# STLUX285A register map
Vendor: STMicroelectronics; Series: STLUX; File version: 1.0
Digital controllers for lighting and power conversion applications with up to 6 programmable PWM generators, 96 MHz PLL, DALI
CPU: other r1p0, big endian, no MPU, no FPU, 4 interrupt priority bits
Registers are 8-bit, read-write, reset 0x0 unless marked. A register's access mark holds for its fields unless they carry their own. Offsets are from the block's base; lines under a group give offsets from that group; [hi:lo] are bit positions; {n}, {i} and the like mark numbered series; 'fields as' and 'values as' point back to an identical list; <NAME> marks a mode.

## Memory map
0x00004800 OPT blocks up to offset 0x80
0x00005000 PORT0 size 0x5
0x00005005 PORT1 size 0x5
0x00005010 MSC blocks up to offset 0x2E
0x0000505A FLASH blocks up to offset 0xE
0x000050B3 RST size 0x1
0x000050B4 CLK blocks up to offset 0x1C
0x000050D1 WDG blocks up to offset 0x12
0x000050F0 AWU size 0x3
0x00005210 I2C blocks up to offset 0xE
0x00005230 UART blocks up to offset 0xB
0x00005340 STMR size 0x9
0x000053C0 DALI size 0xA
0x00005400 ADC size 0x16
0x00005500 SMED0 size 0x24
0x00005540 SMED1 size 0x24
0x00005580 SMED2 size 0x24
0x000055C0 SMED3 size 0x24
0x00005600 SMED4 size 0x24
0x00005640 SMED5 size 0x24
0x00007F60 SYS blocks up to offset 0x21
0x00007F70 ITC size 0x8

## Interrupts
1 Interrupt_IRQ1 (AWU) — Interrupt_IRQ1 interrupt
2 Interrupt_IRQ2 (CLK, ITC) — Interrupt_IRQ2 interrupt
6 Interrupt_IRQ6 (SMED0) — Interrupt_IRQ6 interrupt
7 Interrupt_IRQ7 (SMED1) — Interrupt_IRQ7 interrupt
15 Interrupt_IRQ15 (SMED2) — Interrupt_IRQ15 interrupt
16 Interrupt_IRQ16 (SMED3) — Interrupt_IRQ16 interrupt
17 Interrupt_IRQ17 (UART) — Interrupt_IRQ17 interrupt
18 Interrupt_IRQ18 (UART) — Interrupt_IRQ18 interrupt
19 Interrupt_IRQ19 (I2C) — Interrupt_IRQ19 interrupt
22 Interrupt_IRQ22 (ADC) — Interrupt_IRQ22 interrupt
23 Interrupt_IRQ23 (STMR) — Interrupt_IRQ23 interrupt
24 Interrupt_IRQ24 (FLASH) — Interrupt_IRQ24 interrupt
25 Interrupt_IRQ25 (DALI, WDG) — Interrupt_IRQ25 interrupt
26 Interrupt_IRQ26 (SMED4) — Interrupt_IRQ26 interrupt
27 Interrupt_IRQ27 (SMED5) — Interrupt_IRQ27 interrupt

## ADC
Base 0x00005400
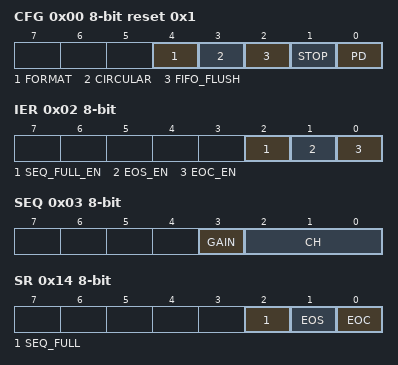
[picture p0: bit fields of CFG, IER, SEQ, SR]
0x00 CFG reset 0x1 — Configuration register
  [4] FORMAT, [3] CIRCULAR, [2] FIFO_FLUSH, [1] STOP, [0] PD
0x01 SOC — Start Of Conversion
  [0] SOC
0x02 IER — Interrupt Enable Register
  [2] SEQ_FULL_EN, [1] EOS_EN, [0] EOC_EN
0x03 SEQ — Sequencer Register
  [3] GAIN, [2:0] CH
{0x4+2i} DATL{i} (i=0..7) — Data Low Register
  [7:0] DATA_LOW
{0x5+2i} DATH{i} (i=0..7) — Data High Register
  [1:0] DATA_HIGH
0x14 SR — Status Register
  [2] SEQ_FULL, [1] EOS, [0] EOC
0x15 DLYCNT — SOC Delay Counter Register
  [7:0] SOC_DLY_CNT

## AWU
Base 0x000050F0
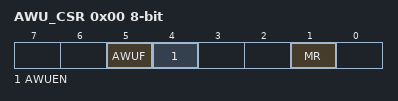
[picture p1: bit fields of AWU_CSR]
0x00 AWU_CSR — AWU control/status register 1
  [5] AWUF, [4] AWUEN, [1] MR
0x01 AWU_APR reset 0x3F — AWU asynchronous prescaler buffer register
  [5:0] APR
0x02 AWU_TBR — AWU timebase selection register
  [3:0] AWUTB

## CLK
Base 0x000050B4
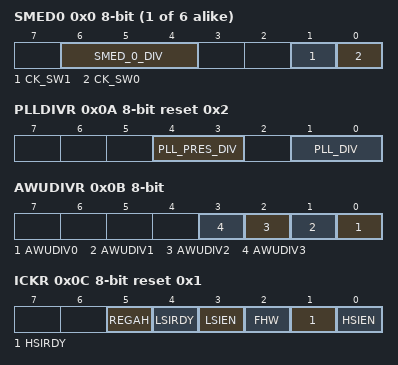
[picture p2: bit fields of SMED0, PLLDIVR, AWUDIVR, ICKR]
{0x0+i} SMED{i} (i=0..5) — SMED{i} clock configuration register
  [6:4] SMED_{i}_DIV, [1] CK_SW1, [0] CK_SW0
0x0A PLLDIVR reset 0x2 — PLL prescaler configuration register
  [4:3] PLL_PRES_DIV, [1:0] PLL_DIV
0x0B AWUDIVR — AWU clock prescaler configuration register
  [n] AWUDIV{n} (n=0..3)
0x0C ICKR reset 0x1 — Internal clock control register
  [5] REGAH, [4] LSIRDY, [3] LSIEN, [2] FHW, [1] HSIRDY, [0] HSIEN
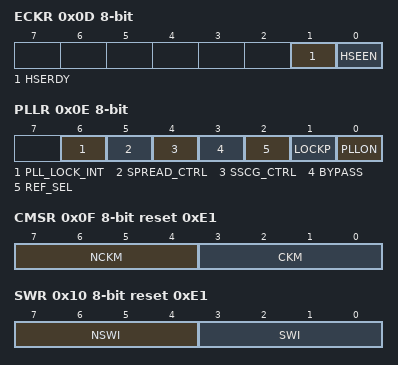
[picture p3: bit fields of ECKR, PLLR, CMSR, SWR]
0x0D ECKR — External clock control register
  [1] HSERDY, [0] HSEEN
0x0E PLLR — External clock control register
  [6] PLL_LOCK_INT, [5] SPREAD_CTRL, [4] SSCG_CTRL, [3] BYPASS, [2] REF_SEL, [1] LOCKP, [0] PLLON
0x0F CMSR reset 0xE1 — Clock master status register
  [7:4] NCKM, [3:0] CKM
0x10 SWR reset 0xE1 — Clock master switch register
  [7:4] NSWI, [3:0] SWI
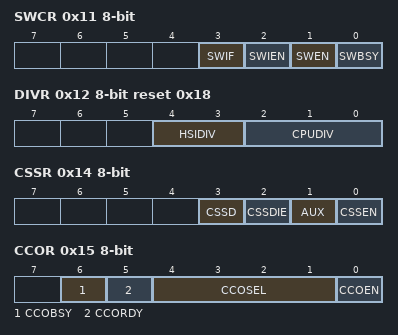
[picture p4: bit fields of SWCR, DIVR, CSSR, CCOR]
0x11 SWCR — Clock switch control register
  [3] SWIF, [2] SWIEN, [1] SWEN, [0] SWBSY
0x12 DIVR reset 0x18 — Clock divider register
  [4:3] HSIDIV, [2:0] CPUDIV
0x13 PCKENR1 reset 0xFF — Peripheral clock gating register 1
  [7:0] PCKEN
0x14 CSSR — Clock security system register
  [3] CSSD, [2] CSSDIE, [1] AUX, [0] CSSEN
0x15 CCOR — Configurable clock control register
  [6] CCOBSY, [5] CCORDY, [4:1] CCOSEL, [0] CCOEN
0x16 PCKENR2 reset 0xFF — Peripheral clock gating register 2
  [7:0] PCKEN
0x18 HSITRIMR — HSI clock calibration trimming register
  [3:0] HSITRIM
0x19 SWIMCCR — SWIM clock control register
  [0] SWIMCLK
0x1A CCODIVR — CCO divider register
  [7:0] CCODIV
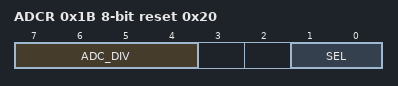
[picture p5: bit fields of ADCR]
0x1B ADCR reset 0x20 — ADC clock configuration register
  [7:4] ADC_DIV, [1:0] SEL
